# GD32W515Px register map
File version: 1.0
CPU: CM33 r0p0, little endian, MPU, FPU, 4 interrupt priority bits
Registers are 32-bit, read-write, reset 0x0 unless marked. A register's access mark holds for its fields unless they carry their own. Offsets are from the block's base; [hi:lo] are bit positions; {n}, {i} and the like mark numbered series.

## TZSPC — TrustZone security controller
Base 0x400A0000
Same registers: SEC_TZSPC 0x500A0000
0x00 CTL — TZSPC control register
  [0] LK — TZSPC items lock configuration bit
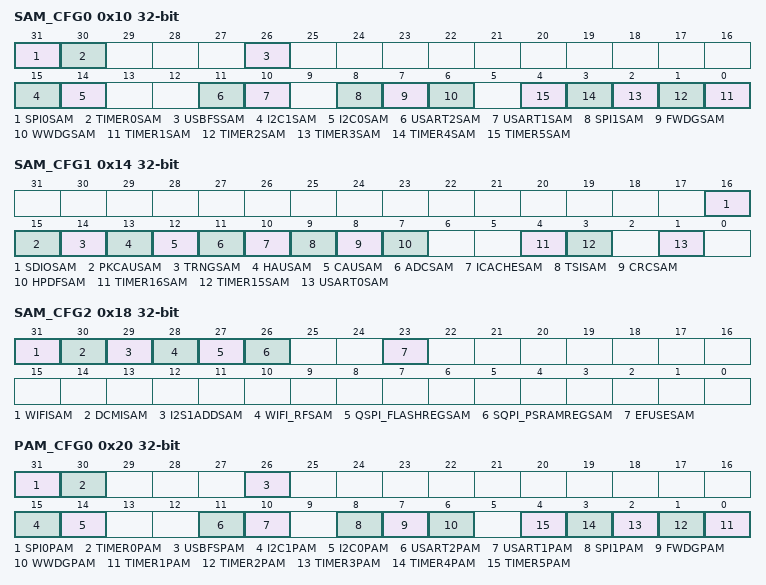
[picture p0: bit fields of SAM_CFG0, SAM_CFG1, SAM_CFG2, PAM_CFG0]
0x10 SAM_CFG0 — TZSPC secure access mode configuration register 0
  [31] SPI0SAM — SPI0 secure access mode configuration bit
  [30] TIMER0SAM — TIMER0 secure access mode configuration bit
  [26] USBFSSAM — USBFS secure access mode configuration bit
  [15] I2C1SAM — I2C1 secure access mode configuration bit
  [14] I2C0SAM — I2C0 secure access mode configuration bit
  [11] USART2SAM — USART2 secure access mode configuration bit
  [10] USART1SAM — USART1 secure access mode configuration bit
  [8] SPI1SAM — SPI1 secure access mode configuration bit
  [7] FWDGSAM — FWDG secure access mode configuration bit
  [6] WWDGSAM — WWDG secure access mode configuration bit
  [n-1] TIMER{n}SAM (n=1..5) — TIMER{n} secure access mode configuration bit
0x14 SAM_CFG1 — TZSPC secure access mode configuration register 1
  [16] SDIOSAM — SDIO secure access mode configuration bit
  [15] PKCAUSAM — PKCAU secure access mode configuration bit
  [14] TRNGSAM — TRNG secure access mode configuration bit
  [13] HAUSAM — HAU secure access mode configuration bit
  [12] CAUSAM — CAU secure access mode configuration bit
  [11] ADCSAM — ADC secure access mode configuration bit
  [10] ICACHESAM — ICACHE secure access mode configuration bit
  [9] TSISAM — TSI secure access mode configuration bit
  [8] CRCSAM — CRC secure access mode configuration bit
  [7] HPDFSAM — HPDF secure access mode configuration bit
  [4] TIMER16SAM — TIMER16 secure access mode configuration bit
  [3] TIMER15SAM — TIMER15 secure access mode configuration bit
  [1] USART0SAM — USART0 secure access mode configuration bit
0x18 SAM_CFG2 — TZSPC secure access mode configuration register 2
  [31] WIFISAM — WIFI secure access mode configuration bit
  [30] DCMISAM — DCMI secure access mode configuration bit
  [29] I2S1ADDSAM — I2S1ADD secure access mode configuration bit
  [28] WIFI_RFSAM — WIFI RF secure access mode configuration bit
  [27] QSPI_FLASHREGSAM — QSPI flash register secure access mode configuration bit
  [26] SQPI_PSRAMREGSAM — SQPI PSRAM register secure access mode configuration bit
  [23] EFUSESAM — EFUSE register secure access mode configuration bit
0x20 PAM_CFG0 read-wirte — TZSPC privilege access mode configuration register1
  [31] SPI0PAM — SPI0 privilege access mode configuration bit
  [30] TIMER0PAM — TIMER0 privilege access mode configuration bit
  [26] USBFSPAM — USBFS privilege access mode configuration bit
  [15] I2C1PAM — I2C1 privilege access mode configuration bit
  [14] I2C0PAM — I2C0 privilege access mode configuration bit
  [11] USART2PAM — USART2 privilege access mode configuration bit
  [10] USART1PAM — USART1 privilege access mode configuration bit
  [8] SPI1PAM — SPI1 privilege access mode configuration bit
  [7] FWDGPAM — FWDG privilege access mode configuration bit
  [6] WWDGPAM — WWDG privilege access mode configuration bit
  [n-1] TIMER{n}PAM (n=1..5) — TIMER{n} privilege access mode configuration bit
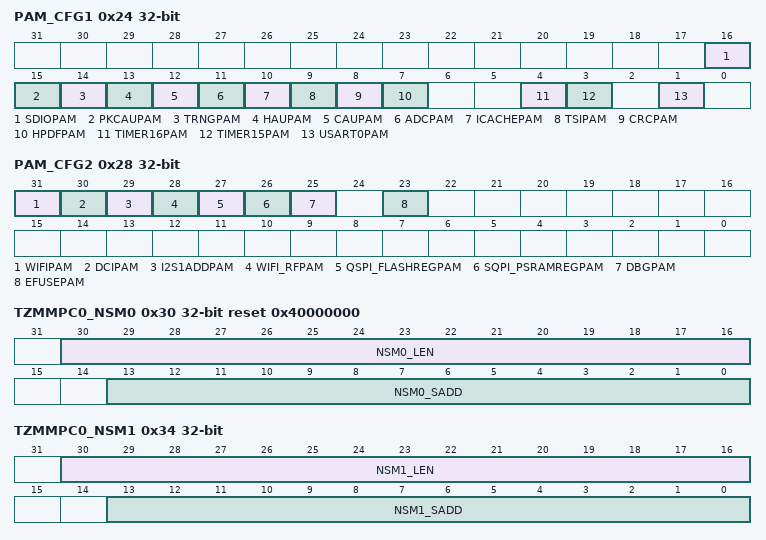
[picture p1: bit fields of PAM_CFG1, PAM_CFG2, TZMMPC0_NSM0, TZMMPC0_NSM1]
0x24 PAM_CFG1 — TZSPC privilege access mode configuration register 1
  [16] SDIOPAM — SDIO privilege access mode configuration bit
  [15] PKCAUPAM — PKCAU privilege access mode configuration bit
  [14] TRNGPAM — TRNG privilege access mode configuration bit
  [13] HAUPAM — HAU privilege access mode configuration bit
  [12] CAUPAM — CAU privilege access mode configuration bit
  [11] ADCPAM — ADC privilege access mode configuration bit
  [10] ICACHEPAM — ICACHE register privilege access mode configuration bit
  [9] TSIPAM — TSI privilege access mode configuration bit
  [8] CRCPAM — CRC privilege access mode configuration bit
  [7] HPDFPAM — HPDF privilege access mode configuration bit
  [4] TIMER16PAM — TIMER16 privilege access mode configuration bit
  [3] TIMER15PAM — TIMER15 privilege access mode configuration bit
  [1] USART0PAM — USART0 privilege access mode configuration bit
0x28 PAM_CFG2 — TZSPC privilege access mode configuration register 2
  [31] WIFIPAM — WIFI privilege access mode configuration bit
  [30] DCIPAM — DCI privilege access mode configuration bit
  [29] I2S1ADDPAM — I2S1ADD privilege access mode configuration bit
  [28] WIFI_RFPAM — WIFI RF privilege access mode configuration bit
  [27] QSPI_FLASHREGPAM — QSPI flash register privilege access mode configuration bit
  [26] SQPI_PSRAMREGPAM — SQPI PSRAM register privilege access mode configuration bit
  [25] DBGPAM — DBG register privilege access mode configuration bit
  [23] EFUSEPAM — EFUSE register privilege access mode configuration bit
0x30 TZMMPC0_NSM0 reset 0x40000000 — TZSPC external memory 0 non-secure mark register 0
  [30:16] NSM0_LEN — Length of the first non-secure area
  [13:0] NSM0_SADD — The non-secure area (multiple of 8 Kbytes) start address of TZBPC0
0x34 TZMMPC0_NSM1 — TZSPC external memory 0 non-secure mark register 1
  [30:16] NSM1_LEN — Length of the first non-secure area
  [13:0] NSM1_SADD — The first non-secure area (multiple of 8 Kbytes) start address
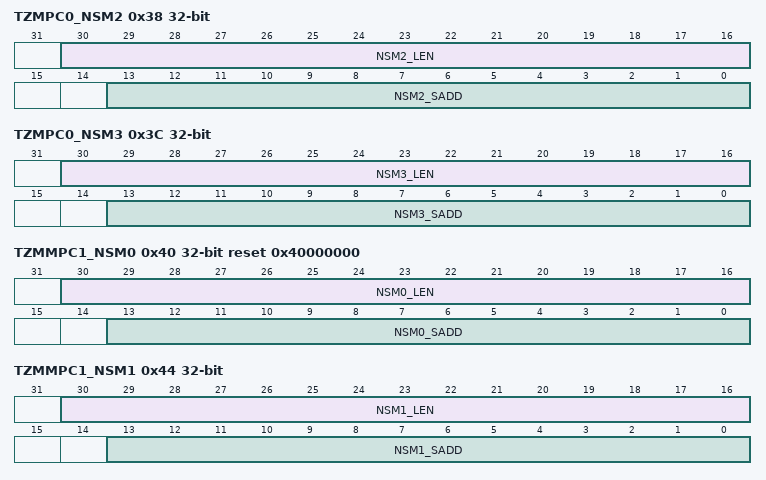
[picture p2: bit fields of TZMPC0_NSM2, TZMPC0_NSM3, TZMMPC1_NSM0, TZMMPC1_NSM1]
0x38 TZMPC0_NSM2 — TZSPC external memory 0 non-secure mark register 2
  [30:16] NSM2_LEN — Length of the non-secure area
  [13:0] NSM2_SADD — The non-secure area (multiple of 8 Kbytes) start address
0x3C TZMPC0_NSM3 — TZSPC external memory 0 non-secure mark register 3
  [30:16] NSM3_LEN — Length of the first non-secure area
  [13:0] NSM3_SADD — The first non-secure area (multiple of 8 Kbytes) start address
0x40 TZMMPC1_NSM0 reset 0x40000000 — TZSPC external memory 1 non-secure mark register 0
  [30:16] NSM0_LEN — Length of the non-secure area
  [13:0] NSM0_SADD — The non-secure area (multiple of 8 Kbytes) start address
0x44 TZMMPC1_NSM1 — TZSPC external memory 1 non-secure mark register 1
  [30:16] NSM1_LEN — Length of the non-secure area
  [13:0] NSM1_SADD — The non-secure area (multiple of 8 Kbytes) start address
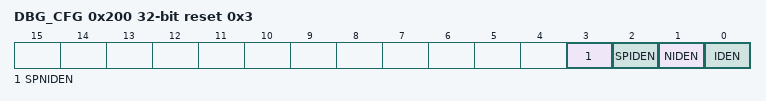
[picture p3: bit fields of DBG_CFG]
0x200 DBG_CFG reset 0x3 — TZSPC debug configuration register
  [3] SPNIDEN — Secure non-invasive debug enable bit
  [2] SPIDEN — Secure invasive debug enable bit
  [1] NIDEN — Non-invasive debug enable bit
  [0] IDEN — Invasive debug enable bit
